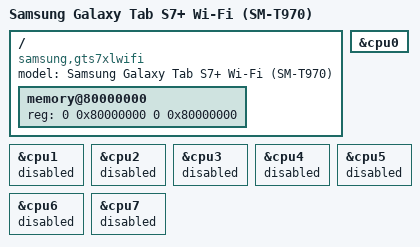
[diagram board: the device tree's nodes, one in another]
/dts-v1/;
/include/ "sm8250.dtsi"

/ {
    model = "Samsung Galaxy Tab S7+ Wi-Fi (SM-T970)";
    compatible = "samsung,gts7xlwifi", "qcom,sm8250";

    // DarwinBoot allocates the kernel window from UEFI conventional memory; on
    // this board that window lands at 0xC0000000. The ADT envelope must contain
    // it, so describe the low 2 GiB span the way the SM-T733 port does: reserved
    // holes stay inside the span and DarwinBoot only claims conventional memory.
    memory@80000000 {
        device_type = "memory";
        reg = <0 0x80000000 0 0x80000000>;
    };
};

/include/ "sm-t970-reserved.dtsi"
/include/ "sm-t970-peripherals.dtsi"

// Keep the first hardware test on the boot CPU. Shared affinities and timer/GIC
// resources were compared with evidence/adb-2026-11-01/live-device-tree.dts.
&cpu0 { status = "okay"; };
&cpu1 { status = "disabled"; };
&cpu2 { status = "disabled"; };
&cpu3 { status = "disabled"; };
&cpu4 { status = "disabled"; };
&cpu5 { status = "disabled"; };
&cpu6 { status = "disabled"; };
&cpu7 { status = "disabled"; };

// Measured board peripheral resources are included above and remain disabled.
